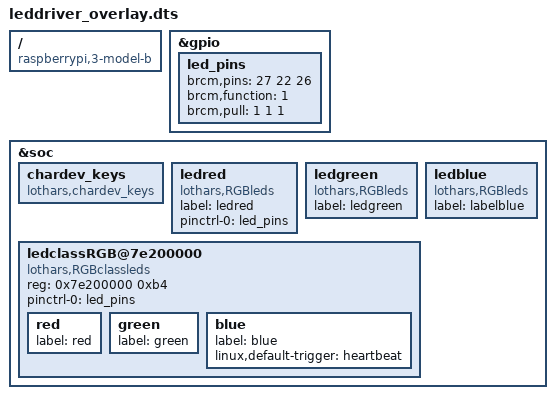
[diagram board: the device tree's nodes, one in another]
/dts-v1/;
/plugin/;
/ {
	compatible = "raspberrypi,3-model-b", "brcm,bcm2835";
	fragment@0 {
		target = <&gpio>;
		__overlay__ {
	 		/*
 			leds: gpios
 			led_pins can be used directly in the sections part of "soc"
 			*/
 			led_pins: led_pins {
 				brcm,pins = <27 22 26>;
 				brcm,function = <1>;   /* output */
 				brcm,pull = <1 1 1>;   /* pull down */
 			};
		};
	};

	fragment@1 {
		target = <&soc>;
		__overlay__ {
			#address-cells = <1>;
			#size-cells = <1>;

 			chardev_keys {
 				compatible = "lothars,chardev_keys";
 			};

 			// leds: colors
 			ledred {
 				compatible = "lothars,RGBleds";
 				label = "ledred";
 				pinctrl-0 = <&led_pins>;
 			};

 			ledgreen {
 				compatible = "lothars,RGBleds";
 				label = "ledgreen";
 			};

 			ledblue {
 				compatible = "lothars,RGBleds";
 				label = "labelblue";
 			};

 			// leds: ledclass stuff also in "soc" section
/*
 			ledclassRGB { // TODO should work w/o regs, then strip down address-cells/size-cells, too
/*/
			ledclassRGB@7e200000 {
 				reg = <0x7e200000 0xb4>; // TODO why is this needed?
// */
 				compatible = "lothars,RGBclassleds";
 				pinctrl-names = "default";

//				pinctrl-0 = <&pinctrl_gpio_leds &pinctrl_gpio_led>;  // TODO needed?
 				// alternatively use the "led_pins" defined
 				// in gpio section
 				pinctrl-0 = <&led_pins>;
 				red {
 					label = "red";
 				};

 				green {
 					label = "green";
 				};

 				blue {
 					label = "blue";
 					linux,default-trigger = "heartbeat";
 				};
 			};
		};
	};
};
